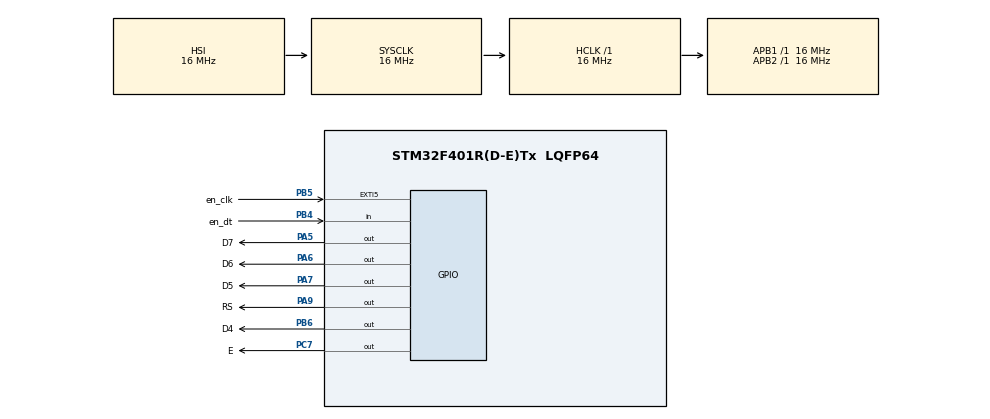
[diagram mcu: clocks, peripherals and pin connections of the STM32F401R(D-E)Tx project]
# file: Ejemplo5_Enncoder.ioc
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Mcu.Family=STM32F4
Mcu.Name=STM32F401R(D-E)Tx
Mcu.Package=LQFP64
NVIC.EXTI9_5_IRQn=true\:0\:0\:false\:false\:true\:true\:true\:true
NVIC.PriorityGroup=NVIC_PRIORITYGROUP_4
PA13.Mode=Serial_Wire
PA13.Signal=SYS_JTMS-SWDIO
PA14.Mode=Serial_Wire
PA14.Signal=SYS_JTCK-SWCLK
PA5.GPIO_Label=D7
PA5.Signal=GPIO_Output
PA6.GPIO_Label=D6
PA6.Signal=GPIO_Output
PA7.GPIO_Label=D5
PA7.Signal=GPIO_Output
PA9.GPIO_Label=RS
PA9.Signal=GPIO_Output
PB4.GPIO_Label=en_dt
PB4.Signal=GPIO_Input
PB5.GPIO_Label=en_clk
PB5.GPIO_ModeDefaultEXTI=GPIO_MODE_IT_RISING_FALLING
PB5.Signal=GPXTI5
PB6.GPIO_Label=D4
PB6.Signal=GPIO_Output
PC7.GPIO_Label=E
PC7.Signal=GPIO_Output
ProjectManager.HeapSize=0x200
ProjectManager.StackSize=0x400
ProjectManager.TargetToolchain=STM32CubeIDE
RCC.AHBFreq_Value=16000000
RCC.APB1Freq_Value=16000000
RCC.APB2Freq_Value=16000000
RCC.CortexFreq_Value=16000000
RCC.HSE_VALUE=25000000
RCC.HSI_VALUE=16000000
RCC.LSE_VALUE=32768
RCC.SYSCLKFreq_VALUE=16000000
RCC.VCOOutputFreq_Value=192000000
board=custom

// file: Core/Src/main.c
/* USER CODE BEGIN Header */
/**
  ******************************************************************************
  * @file           : main.c
  * @brief          : Main program body
  ******************************************************************************
  * @attention
  *
  * Copyright (c) 2023 STMicroelectronics.
  * All rights reserved.
  *
  * This software is licensed under terms that can be found in the LICENSE file
  * in the root directory of this software component.
  * If no LICENSE file comes with this software, it is provided AS-IS.
  *
  ******************************************************************************
  */
/* USER CODE END Header */
#include "main.h"

/* USER CODE BEGIN Includes */
#include "LCD.h"
#include "stdio.h"
/* USER CODE END Includes */

void SystemClock_Config(void);
static void MX_GPIO_Init(void);

/* USER CODE BEGIN 0 */
extern volatile uint16_t contador_posicion;
extern volatile uint16_t artificio;
char stri_contador[10];
/* USER CODE END 0 */

int main(void)
{

  /* MCU Configuration--------------------------------------------------------*/

  /* Reset of all peripherals, Initializes the Flash interface and the Systick. */
  HAL_Init();

  /* Configure the system clock */
  SystemClock_Config();

  /* Initialize all configured peripherals */
  MX_GPIO_Init();
  /* USER CODE BEGIN 2 */
LCD_STM32_INIT();
LCD_STM32_SET_CURSOR(0, fila1);
LCD_STM32_PRINT_STRING("La cuenta es:");
  /* USER CODE END 2 */

  /* Infinite loop */
  /* USER CODE BEGIN WHILE */
  while (1)
  {
	  sprintf(stri_contador,"%04u",contador_posicion);
		  LCD_STM32_SET_CURSOR(0, fila2);
		  LCD_STM32_PRINT_STRING(stri_contador);
		  HAL_Delay(500);
    /* USER CODE END WHILE */

  }
}

void SystemClock_Config(void)
{
  RCC_OscInitTypeDef RCC_OscInitStruct = {0};
  RCC_ClkInitTypeDef RCC_ClkInitStruct = {0};

  /** Configure the main internal regulator output voltage
  */
  __HAL_RCC_PWR_CLK_ENABLE();
  __HAL_PWR_VOLTAGESCALING_CONFIG(PWR_REGULATOR_VOLTAGE_SCALE2);

  /** Initializes the RCC Oscillators according to the specified parameters
  * in the RCC_OscInitTypeDef structure.
  */
  RCC_OscInitStruct.OscillatorType = RCC_OSCILLATORTYPE_HSI;
  RCC_OscInitStruct.HSIState = RCC_HSI_ON;
  RCC_OscInitStruct.HSICalibrationValue = RCC_HSICALIBRATION_DEFAULT;
  RCC_OscInitStruct.PLL.PLLState = RCC_PLL_NONE;
  if (HAL_RCC_OscConfig(&RCC_OscInitStruct) != HAL_OK)
  {
    Error_Handler();
  }

  /** Initializes the CPU, AHB and APB buses clocks
  */
  RCC_ClkInitStruct.ClockType = RCC_CLOCKTYPE_HCLK|RCC_CLOCKTYPE_SYSCLK
                              |RCC_CLOCKTYPE_PCLK1|RCC_CLOCKTYPE_PCLK2;
  RCC_ClkInitStruct.SYSCLKSource = RCC_SYSCLKSOURCE_HSI;
  RCC_ClkInitStruct.AHBCLKDivider = RCC_SYSCLK_DIV1;
  RCC_ClkInitStruct.APB1CLKDivider = RCC_HCLK_DIV1;
  RCC_ClkInitStruct.APB2CLKDivider = RCC_HCLK_DIV1;

  if (HAL_RCC_ClockConfig(&RCC_ClkInitStruct, FLASH_LATENCY_0) != HAL_OK)
  {
    Error_Handler();
  }
}

static void MX_GPIO_Init(void)
{
  GPIO_InitTypeDef GPIO_InitStruct = {0};

  /* GPIO Ports Clock Enable */
  __HAL_RCC_GPIOA_CLK_ENABLE();
  __HAL_RCC_GPIOC_CLK_ENABLE();
  __HAL_RCC_GPIOB_CLK_ENABLE();

  /*Configure GPIO pin Output Level */
  HAL_GPIO_WritePin(GPIOA, D7_Pin|D6_Pin|D5_Pin|RS_Pin, GPIO_PIN_RESET);

  /*Configure GPIO pin Output Level */
  HAL_GPIO_WritePin(E_GPIO_Port, E_Pin, GPIO_PIN_RESET);

  /*Configure GPIO pin Output Level */
  HAL_GPIO_WritePin(D4_GPIO_Port, D4_Pin, GPIO_PIN_RESET);

  /*Configure GPIO pins : D7_Pin D6_Pin D5_Pin RS_Pin */
  GPIO_InitStruct.Pin = D7_Pin|D6_Pin|D5_Pin|RS_Pin;
  GPIO_InitStruct.Mode = GPIO_MODE_OUTPUT_PP;
  GPIO_InitStruct.Pull = GPIO_NOPULL;
  GPIO_InitStruct.Speed = GPIO_SPEED_FREQ_LOW;
  HAL_GPIO_Init(GPIOA, &GPIO_InitStruct);

  /*Configure GPIO pin : E_Pin */
  GPIO_InitStruct.Pin = E_Pin;
  GPIO_InitStruct.Mode = GPIO_MODE_OUTPUT_PP;
  GPIO_InitStruct.Pull = GPIO_NOPULL;
  GPIO_InitStruct.Speed = GPIO_SPEED_FREQ_LOW;
  HAL_GPIO_Init(E_GPIO_Port, &GPIO_InitStruct);

  /*Configure GPIO pin : en_dt_Pin */
  GPIO_InitStruct.Pin = en_dt_Pin;
  GPIO_InitStruct.Mode = GPIO_MODE_INPUT;
  GPIO_InitStruct.Pull = GPIO_NOPULL;
  HAL_GPIO_Init(en_dt_GPIO_Port, &GPIO_InitStruct);

  /*Configure GPIO pin : en_clk_Pin */
  GPIO_InitStruct.Pin = en_clk_Pin;
  GPIO_InitStruct.Mode = GPIO_MODE_IT_RISING_FALLING;
  GPIO_InitStruct.Pull = GPIO_NOPULL;
  HAL_GPIO_Init(en_clk_GPIO_Port, &GPIO_InitStruct);

  /*Configure GPIO pin : D4_Pin */
  GPIO_InitStruct.Pin = D4_Pin;
  GPIO_InitStruct.Mode = GPIO_MODE_OUTPUT_PP;
  GPIO_InitStruct.Pull = GPIO_NOPULL;
  GPIO_InitStruct.Speed = GPIO_SPEED_FREQ_LOW;
  HAL_GPIO_Init(D4_GPIO_Port, &GPIO_InitStruct);

  /* EXTI interrupt init*/
  HAL_NVIC_SetPriority(EXTI9_5_IRQn, 0, 0);
  HAL_NVIC_EnableIRQ(EXTI9_5_IRQn);

}

void Error_Handler(void)
{
  __disable_irq();
  while (1)
  {
  }
}
